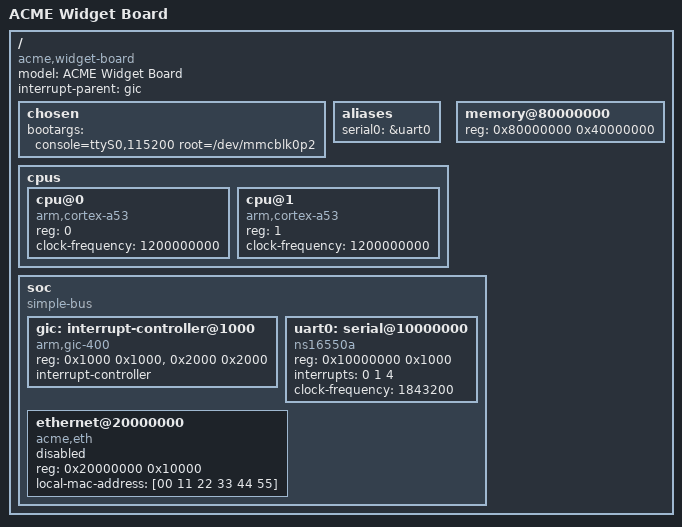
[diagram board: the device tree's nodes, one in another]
/dts-v1/;

/memreserve/ 0x88000000 0x00100000;
/memreserve/ 0x8a000000 0x00002000;

/ {
	compatible = "acme,widget-board", "acme,widget";
	model = "ACME Widget Board";
	#address-cells = <1>;
	#size-cells = <1>;
	interrupt-parent = <&gic>;

	chosen {
		bootargs = "console=ttyS0,115200 root=/dev/mmcblk0p2";
	};

	aliases {
		serial0 = &uart0;
	};

	cpus {
		#address-cells = <1>;
		#size-cells = <0>;

		cpu@0 {
			device_type = "cpu";
			compatible = "arm,cortex-a53";
			reg = <0>;
			clock-frequency = <1200000000>;
		};

		cpu@1 {
			device_type = "cpu";
			compatible = "arm,cortex-a53";
			reg = <1>;
			clock-frequency = <1200000000>;
		};
	};

	memory@80000000 {
		device_type = "memory";
		reg = <0x80000000 0x40000000>;
	};

	soc {
		compatible = "simple-bus";
		#address-cells = <1>;
		#size-cells = <1>;
		ranges;

		gic: interrupt-controller@1000 {
			compatible = "arm,gic-400";
			reg = <0x1000 0x1000>, <0x2000 0x2000>;
			interrupt-controller;
			#interrupt-cells = <3>;
		};

		uart0: serial@10000000 {
			compatible = "ns16550a";
			reg = <0x10000000 0x1000>;
			interrupts = <0 1 4>;
			clock-frequency = <1843200>;
			status = "okay";
		};

		ethernet@20000000 {
			compatible = "acme,eth";
			reg = <0x20000000 0x10000>;
			local-mac-address = [00 11 22 33 44 55];
			status = "disabled";
		};
	};
};
